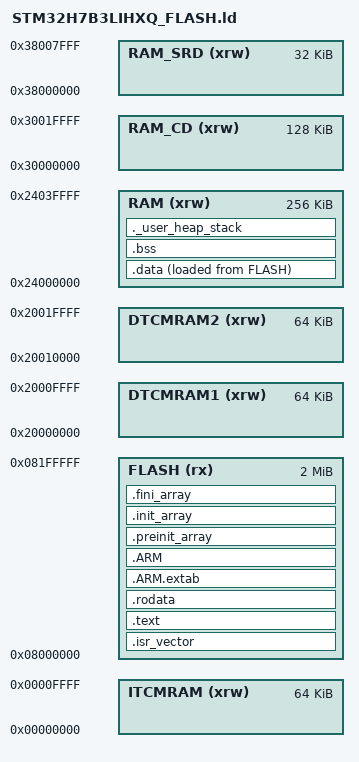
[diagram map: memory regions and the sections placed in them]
/*
******************************************************************************
**
**  File        : LinkerScript.ld
**
**  Author		: Auto-generated by STM32CubeIDE
**
**  Abstract    : Linker script for STM32H7B3LIHxQ Device from STM32H7 series
**                      2048Kbytes ROM
**                      128Kbytes RAM
**
**                Set heap size, stack size and stack location according
**                to application requirements.
**
**                Set memory bank area and size if external memory is used.
**
**  Target      : STMicroelectronics STM32
**
**  Distribution: The file is distributed as is without any warranty
**                of any kind.
**
*****************************************************************************
** @attention
**
** <h2><center>&copy; COPYRIGHT(c) 2019 STMicroelectronics</center></h2>
**
** Redistribution and use in source and binary forms, with or without modification,
** are permitted provided that the following conditions are met:
**   1. Redistributions of source code must retain the above copyright notice,
**      this list of conditions and the following disclaimer.
**   2. Redistributions in binary form must reproduce the above copyright notice,
**      this list of conditions and the following disclaimer in the documentation
**      and/or other materials provided with the distribution.
**   3. Neither the name of STMicroelectronics nor the names of its contributors
**      may be used to endorse or promote products derived from this software
**      without specific prior written permission.
**
** THIS SOFTWARE IS PROVIDED BY THE COPYRIGHT HOLDERS AND CONTRIBUTORS "AS IS"
** AND ANY EXPRESS OR IMPLIED WARRANTIES, INCLUDING, BUT NOT LIMITED TO, THE
** IMPLIED WARRANTIES OF MERCHANTABILITY AND FITNESS FOR A PARTICULAR PURPOSE ARE
** DISCLAIMED. IN NO EVENT SHALL THE COPYRIGHT HOLDER OR CONTRIBUTORS BE LIABLE
** FOR ANY DIRECT, INDIRECT, INCIDENTAL, SPECIAL, EXEMPLARY, OR CONSEQUENTIAL
** DAMAGES (INCLUDING, BUT NOT LIMITED TO, PROCUREMENT OF SUBSTITUTE GOODS OR
** SERVICES; LOSS OF USE, DATA, OR PROFITS; OR BUSINESS INTERRUPTION) HOWEVER
** CAUSED AND ON ANY THEORY OF LIABILITY, WHETHER IN CONTRACT, STRICT LIABILITY,
** OR TORT (INCLUDING NEGLIGENCE OR OTHERWISE) ARISING IN ANY WAY OUT OF THE USE
** OF THIS SOFTWARE, EVEN IF ADVISED OF THE POSSIBILITY OF SUCH DAMAGE.
**
*****************************************************************************
*/

/* Entry Point */
ENTRY(Reset_Handler)

/* Generate a link error if heap and stack don't fit into RAM */
_Min_Heap_Size  = __HEAP_SIZE;    /* required amount of heap  */
_Min_Stack_Size = __STACK_SIZE;   /* required amount of stack */

/* Memories definition */
MEMORY
{

    FLASH           (rx)  : ORIGIN = 0x08000000, LENGTH = 2048K
    RAM             (xrw) : ORIGIN = 0x24000000, LENGTH = 256K  /* 1024K */
    ITCMRAM         (xrw) : ORIGIN = 0x00000000, LENGTH = 64K
    DTCMRAM1        (xrw) : ORIGIN = 0x20000000, LENGTH = 64K
    DTCMRAM2        (xrw) : ORIGIN = 0x20010000, LENGTH = 64K
    RAM_CD          (xrw) : ORIGIN = 0x30000000, LENGTH = 128K
    RAM_SRD         (xrw) : ORIGIN = 0x38000000, LENGTH = 32K
   /* GFX_DISPLAY   (rwx) : ORIGIN = 0xC0000000, LENGTH = 15M*/
   /* GFX_RAM_DBASE (rwx) : ORIGIN = 0xC0F00000, LENGTH = 1M*/
}

/* Highest address of the user mode stack */
_estack = ORIGIN(RAM) + LENGTH(RAM);
_StackBottom = _estack - __STACK_SIZE;

/* Define output sections */
SECTIONS
{
  /* The startup code goes first into FLASH */
  .isr_vector :
  {
    . = ALIGN(4);
    KEEP(*(.isr_vector)) /* Startup code */
    . = ALIGN(4);
  } >FLASH

  /* The program code and other data goes into FLASH */
  .text :
  {
    . = ALIGN(4);
    *(.text)           /* .text sections (code) */
    *(.text*)          /* .text* sections (code) */
    *(.glue_7)         /* glue arm to thumb code */
    *(.glue_7t)        /* glue thumb to arm code */
    *(.eh_frame)

    KEEP (*(.init))
    KEEP (*(.fini))

    . = ALIGN(4);
    _etext = .;        /* define a global symbols at end of code */
  } >FLASH

  /* Constant data goes into FLASH */
  .rodata :
  {
    . = ALIGN(4);
    *(.rodata)         /* .rodata sections (constants, strings, etc.) */
    *(.rodata*)        /* .rodata* sections (constants, strings, etc.) */
    . = ALIGN(4);
  } >FLASH

  .ARM.extab   :
  {
    . = ALIGN(4);
    *(.ARM.extab* .gnu.linkonce.armextab.*)
    . = ALIGN(4);
  } >FLASH
  .ARM :
  {
    . = ALIGN(4);
    __exidx_start = .;
    *(.ARM.exidx*)
    __exidx_end = .;
    . = ALIGN(4);
  } >FLASH

  .preinit_array :
  {
    . = ALIGN(4);
    PROVIDE_HIDDEN (__preinit_array_start = .);
    KEEP (*(.preinit_array*))
    PROVIDE_HIDDEN (__preinit_array_end = .);
    . = ALIGN(4);
  } >FLASH

  .init_array :
  {
    . = ALIGN(4);
    PROVIDE_HIDDEN (__init_array_start = .);
    KEEP (*(SORT(.init_array.*)))
    KEEP (*(.init_array*))
    PROVIDE_HIDDEN (__init_array_end = .);
    . = ALIGN(4);
  } >FLASH

  .fini_array :
  {
    . = ALIGN(4);
    PROVIDE_HIDDEN (__fini_array_start = .);
    KEEP (*(SORT(.fini_array.*)))
    KEEP (*(.fini_array*))
    PROVIDE_HIDDEN (__fini_array_end = .);
    . = ALIGN(4);
  } >FLASH

  /* used by the startup to initialize data */
  _sidata = LOADADDR(.data);

  /* Initialized data sections goes into RAM, load LMA copy after code */
  .data :
  {
    . = ALIGN(4);
    _sdata = .;        /* create a global symbol at data start */
    *(.data)           /* .data sections */
    *(.data*)          /* .data* sections */
    *(.RamFunc)        /* .RamFunc sections */
    *(.RamFunc*)       /* .RamFunc* sections */

    . = ALIGN(4);
    _edata = .;        /* define a global symbol at data end */
  } >RAM AT> FLASH

  /* Uninitialized data section */
  . = ALIGN(4);
  .bss :
  {
    /* This is used by the startup in order to initialize the .bss section */
    _sbss = .;         /* define a global symbol at bss start */
    __bss_start__ = _sbss;
    *(.bss)
    *(.bss*)
    *(COMMON)

    . = ALIGN(4);
    _ebss = .;         /* define a global symbol at bss end */
    __bss_end__ = _ebss;
  } >RAM

  /* User_heap_stack section, used to check that there is enough RAM left */
  ._user_heap_stack :
  {
    . = ALIGN(8);
    PROVIDE ( end = . );
    PROVIDE ( _end = . );
    . = . + _Min_Heap_Size;
    . = . + _Min_Stack_Size;
    __HeapLimit = .;
    . = ALIGN(8);
  } >RAM

  /* Remove information from the compiler libraries */
  /DISCARD/ :
  {
    libc.a ( * )
    libm.a ( * )
    libgcc.a ( * )
  }

  .ARM.attributes 0 : { *(.ARM.attributes) }


    __StackLimit = _estack - _Min_Stack_Size;

/*  __gfx_display_base__   = ORIGIN(GFX_DISPLAY);*/
/*	__gfx_ram_data_base__  = ORIGIN(GFX_RAM_DBASE);*/
/*	__user_ram_data_base__ = ORIGIN(RAM_DBASE); */
/*	__gfx_qspi_data_base__ = ORIGIN(GFX_QSPI_DBASE); */

    /* Check if data + heap + stack exceeds RAM limit */
    ASSERT(__StackLimit >= __HeapLimit, "Region RAM overflowed with stack")

}
